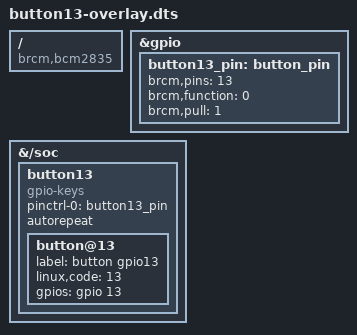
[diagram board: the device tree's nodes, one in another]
/dts-v1/;
/plugin/;

/ {
    compatible = "brcm,bcm2835", "brcm,bcm2708", "brcm,bcm2709";

    fragment@0 {
        target = <&gpio>;
        __overlay__ {
            button13_pin: button_pin {
                brcm,pins = <13>;     /* gpio13 */
                brcm,function = <0>; /* input */
                brcm,pull = <1>;     /* pull-down */
            };
        };
    };

    fragment@1 {
    target-path = "/soc";
        __overlay__ {
            button13: button13 {
                compatible = "gpio-keys";
                #address-cells = <1>;
                #size-cells = <0>;
                pinctrl-names = "default";
                pinctrl-0 = <&button13_pin>;
                status = "okay";
                autorepeat;

                button@13 {
                    label = "button gpio13";
                    linux,code = <13>;
                    gpios = <&gpio 13 0>;
                };
            };
        };
    };
};

